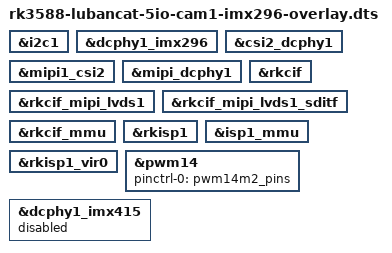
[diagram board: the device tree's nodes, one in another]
/dts-v1/;
/plugin/;

#include <dt-bindings/usb/pd.h>
#include <dt-bindings/gpio/gpio.h>
#include <dt-bindings/pwm/pwm.h>
#include <dt-bindings/pinctrl/rockchip.h>
#include <dt-bindings/input/rk-input.h>
#include <dt-bindings/display/drm_mipi_dsi.h>
#include <dt-bindings/display/rockchip_vop.h>
#include <dt-bindings/sensor-dev.h>

/ {
	/* Link path: sensor->csi2_dcphy1->mipi1_csi2->rkcif_mipi_lvds1->rkcif_mipi_lvds1_sditf->rkisp1_vir0 */
	/* IMX296 template node and 1-lane graph endpoint live in rk3588-lubancat-5io-csi.dtsi. */
	fragment@0 {
		target = <&i2c1>;
		__overlay__ {
			status = "okay";
		};
	};

	fragment@1 {
		target = <&dcphy1_imx296>;
		__overlay__ {
			status = "okay";
		};
	};

	fragment@3 {
		target = <&csi2_dcphy1>;
		__overlay__ {
			status = "okay";
		};
	};

	fragment@4 {
		target = <&mipi1_csi2>;
		__overlay__ {
			status = "okay";
		};
	};

	fragment@5 {
		target = <&mipi_dcphy1>;
		__overlay__ {
			status = "okay";
		};
	};

	fragment@6 {
		target = <&rkcif>;
		__overlay__ {
			status = "okay";
		};
	};

	fragment@7 {
		target = <&rkcif_mipi_lvds1>;
		__overlay__ {
			status = "okay";
		};
	};

	fragment@8 {
		target = <&rkcif_mipi_lvds1_sditf>;
		__overlay__ {
			status = "okay";
		};
	};

	fragment@9 {
		target = <&rkcif_mmu>;
		__overlay__ {
			status = "okay";
		};
	};

	fragment@10 {
		target = <&rkisp1>;
		__overlay__ {
			status = "okay";
		};
	};

	fragment@11 {
		target = <&isp1_mmu>;
		__overlay__ {
			status = "okay";
		};
	};

	fragment@12 {
		target = <&rkisp1_vir0>;
		__overlay__ {
			status = "okay";
		};
	};

	fragment@13 {
		target = <&pwm14>;
		__overlay__ {
			status = "okay";
			pinctrl-names = "active";
			pinctrl-0 = <&pwm14m2_pins>;
		};
	};

	fragment@14 {
		target = <&dcphy1_imx415>;
		__overlay__ {
			/*
			 * Keep cam1 IMX415 disabled when IMX296 is selected on
			 * the same slot to avoid two active sensor definitions
			 * racing for I2C address 0x1a.
			 */
			status = "disabled";
		};
	};
};
